AUTOSAR XML (schema 4-2-2)
package /ComponentTypes
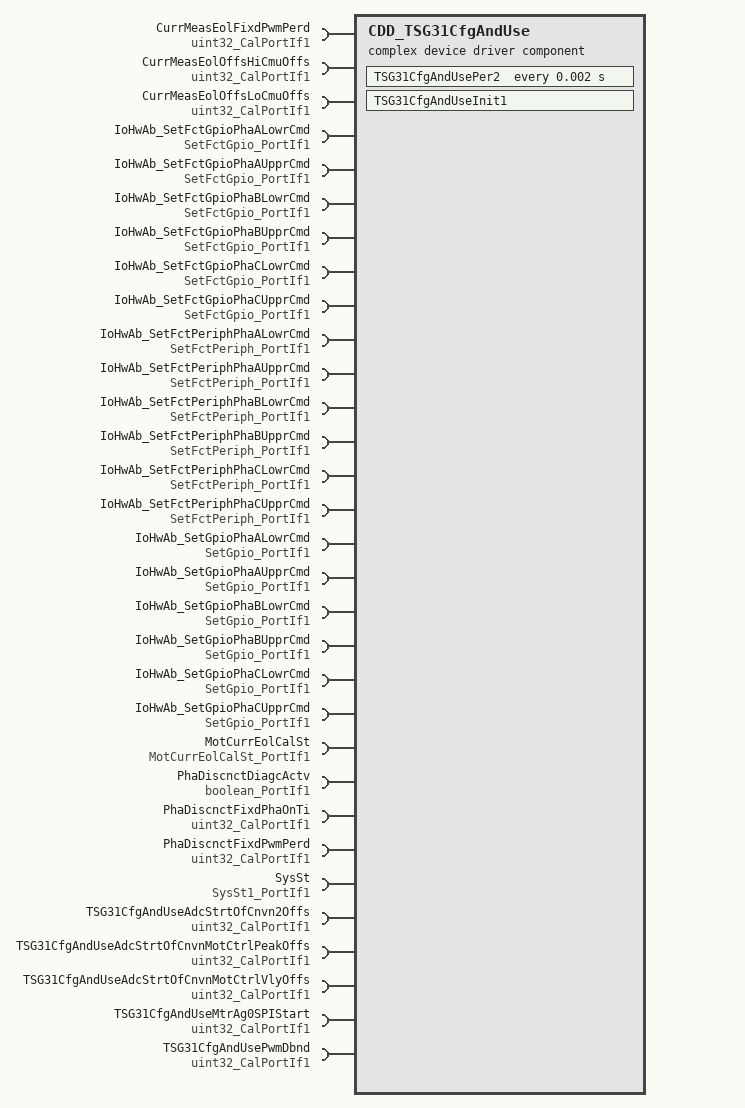
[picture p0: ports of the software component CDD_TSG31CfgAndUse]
  complex device driver sw component type CDD_TSG31CfgAndUse
    31 x require port:
      CurrMeasEolFixdPwmPerd: parameter-require-com-spec{init-value=62500, parameter=Val}, required-interface=uint32_CalPortIf1
      CurrMeasEolOffsHiCmuOffs: parameter-require-com-spec{init-value=50000, parameter=Val}, required-interface=uint32_CalPortIf1
      CurrMeasEolOffsLoCmuOffs: parameter-require-com-spec{init-value=6250, parameter=Val}, required-interface=uint32_CalPortIf1
      IoHwAb_SetFctGpioPhaALowrCmd: client-com-spec=Oper, required-interface=SetFctGpio_PortIf1
      IoHwAb_SetFctGpioPhaAUpprCmd: client-com-spec=Oper, required-interface=SetFctGpio_PortIf1
      IoHwAb_SetFctGpioPhaBLowrCmd: client-com-spec=Oper, required-interface=SetFctGpio_PortIf1
      IoHwAb_SetFctGpioPhaBUpprCmd: client-com-spec=Oper, required-interface=SetFctGpio_PortIf1
      IoHwAb_SetFctGpioPhaCLowrCmd: client-com-spec=Oper, required-interface=SetFctGpio_PortIf1
      IoHwAb_SetFctGpioPhaCUpprCmd: client-com-spec=Oper, required-interface=SetFctGpio_PortIf1
      IoHwAb_SetFctPeriphPhaALowrCmd: client-com-spec=Oper, required-interface=SetFctPeriph_PortIf1
      IoHwAb_SetFctPeriphPhaAUpprCmd: client-com-spec=Oper, required-interface=SetFctPeriph_PortIf1
      IoHwAb_SetFctPeriphPhaBLowrCmd: client-com-spec=Oper, required-interface=SetFctPeriph_PortIf1
      IoHwAb_SetFctPeriphPhaBUpprCmd: client-com-spec=Oper, required-interface=SetFctPeriph_PortIf1
      IoHwAb_SetFctPeriphPhaCLowrCmd: client-com-spec=Oper, required-interface=SetFctPeriph_PortIf1
      IoHwAb_SetFctPeriphPhaCUpprCmd: client-com-spec=Oper, required-interface=SetFctPeriph_PortIf1
      IoHwAb_SetGpioPhaALowrCmd: client-com-spec=Oper, required-interface=SetGpio_PortIf1
      IoHwAb_SetGpioPhaAUpprCmd: client-com-spec=Oper, required-interface=SetGpio_PortIf1
      IoHwAb_SetGpioPhaBLowrCmd: client-com-spec=Oper, required-interface=SetGpio_PortIf1
      IoHwAb_SetGpioPhaBUpprCmd: client-com-spec=Oper, required-interface=SetGpio_PortIf1
      IoHwAb_SetGpioPhaCLowrCmd: client-com-spec=Oper, required-interface=SetGpio_PortIf1
      IoHwAb_SetGpioPhaCUpprCmd: client-com-spec=Oper, required-interface=SetGpio_PortIf1
      MotCurrEolCalSt: nonqueued-receiver-com-spec{data-element=Val, filter=data-filter-type=ALWAYS, init-value=0}, required-interface=MotCurrEolCalSt_PortIf1
      PhaDiscnctDiagcActv: nonqueued-receiver-com-spec{data-element=Logl, filter=data-filter-type=ALWAYS, init-value=0}, required-interface=boolean_PortIf1
      PhaDiscnctFixdPhaOnTi: parameter-require-com-spec{init-value=6250, parameter=Val}, required-interface=uint32_CalPortIf1
      PhaDiscnctFixdPwmPerd: parameter-require-com-spec{init-value=62500, parameter=Val}, required-interface=uint32_CalPortIf1
      SysSt: nonqueued-receiver-com-spec{data-element=Val, filter=data-filter-type=ALWAYS, init-value=3}, required-interface=SysSt1_PortIf1
      TSG31CfgAndUseAdcStrtOfCnvn2Offs: parameter-require-com-spec{init-value=5000, parameter=Val}, required-interface=uint32_CalPortIf1
      TSG31CfgAndUseAdcStrtOfCnvnMotCtrlPeakOffs: parameter-require-com-spec{init-value=6000, parameter=Val}, required-interface=uint32_CalPortIf1
      TSG31CfgAndUseAdcStrtOfCnvnMotCtrlVlyOffs: parameter-require-com-spec{init-value=7000, parameter=Val}, required-interface=uint32_CalPortIf1
      TSG31CfgAndUseMtrAg0SPIStart: parameter-require-com-spec{init-value=1000, parameter=Val}, required-interface=uint32_CalPortIf1
      TSG31CfgAndUsePwmDbnd: parameter-require-com-spec{init-value=200, parameter=Val}, required-interface=uint32_CalPortIf1
    behavior CDD_TSG31CfgAndUse_InternalBehavior
      ar-typed-per-instance-memorys:
        9 x data, all with sw-calibration-access=READ-ONLY:
          MissUpdCoarse: type=uint16
          MissUpdFine: type=uint16
          MissUpdIninCntr: type=uint8
          MissUpdMaxCntr: type=uint16
          MissUpdMinCntr: type=uint16
          TSG31CfgAndUseAdcStrtOfCnvnPeak: type=uint32
          TSG31CfgAndUseMotAg0SPIStart: type=uint32
          TSG31CfgAndUsePhaDiscntActvdStPrev: type=boolean
          TSG31CfgAndUseSysStEnaPrev: type=boolean
      init event CDD_TSG31CfgAndUse_InitEvent: start-on-event=TSG31CfgAndUseInit1
      timing event TMT_TSG31CfgAndUsePer2: start-on-event=TSG31CfgAndUsePer2, period=0.002
      runnable TSG31CfgAndUseInit1
        12 x sync call, all with timeout=0:
          SC_IoHwAb_SetFctGpioPhaALowrCmd_Oper: operation=IoHwAb_SetFctGpioPhaALowrCmd.Oper
          SC_IoHwAb_SetFctGpioPhaAUpprCmd_Oper: operation=IoHwAb_SetFctGpioPhaAUpprCmd.Oper
          SC_IoHwAb_SetFctGpioPhaBLowrCmd_Oper: operation=IoHwAb_SetFctGpioPhaBLowrCmd.Oper
          SC_IoHwAb_SetFctGpioPhaBUpprCmd_Oper: operation=IoHwAb_SetFctGpioPhaBUpprCmd.Oper
          SC_IoHwAb_SetFctGpioPhaCLowrCmd_Oper: operation=IoHwAb_SetFctGpioPhaCLowrCmd.Oper
          SC_IoHwAb_SetFctGpioPhaCUpprCmd_Oper: operation=IoHwAb_SetFctGpioPhaCUpprCmd.Oper
          SC_IoHwAb_SetGpioPhaALowrCmd_Oper: operation=IoHwAb_SetGpioPhaALowrCmd.Oper
          SC_IoHwAb_SetGpioPhaAUpprCmd_Oper: operation=IoHwAb_SetGpioPhaAUpprCmd.Oper
          SC_IoHwAb_SetGpioPhaBLowrCmd_Oper: operation=IoHwAb_SetGpioPhaBLowrCmd.Oper
          SC_IoHwAb_SetGpioPhaBUpprCmd_Oper: operation=IoHwAb_SetGpioPhaBUpprCmd.Oper
          SC_IoHwAb_SetGpioPhaCLowrCmd_Oper: operation=IoHwAb_SetGpioPhaCLowrCmd.Oper
          SC_IoHwAb_SetGpioPhaCUpprCmd_Oper: operation=IoHwAb_SetGpioPhaCUpprCmd.Oper
      runnable TSG31CfgAndUsePer2
        data-receive-point-by-arguments:
          access REC_MotCurrEolCalSt_Val: accessed-variable=MotCurrEolCalSt.Val
          access REC_PhaDiscnctDiagcActv_Logl: accessed-variable=PhaDiscnctDiagcActv.Logl
          access REC_SysSt_Val: accessed-variable=SysSt.Val
        18 x sync call, all with timeout=0:
          SC_IoHwAb_SetFctGpioPhaALowrCmd_Oper: operation=IoHwAb_SetFctGpioPhaALowrCmd.Oper
          SC_IoHwAb_SetFctGpioPhaAUpprCmd_Oper: operation=IoHwAb_SetFctGpioPhaAUpprCmd.Oper
          SC_IoHwAb_SetFctGpioPhaBLowrCmd_Oper: operation=IoHwAb_SetFctGpioPhaBLowrCmd.Oper
          SC_IoHwAb_SetFctGpioPhaBUpprCmd_Oper: operation=IoHwAb_SetFctGpioPhaBUpprCmd.Oper
          SC_IoHwAb_SetFctGpioPhaCLowrCmd_Oper: operation=IoHwAb_SetFctGpioPhaCLowrCmd.Oper
          SC_IoHwAb_SetFctGpioPhaCUpprCmd_Oper: operation=IoHwAb_SetFctGpioPhaCUpprCmd.Oper
          SC_IoHwAb_SetFctPeriphPhaALowrCmd_Oper: operation=IoHwAb_SetFctPeriphPhaALowrCmd.Oper
          SC_IoHwAb_SetFctPeriphPhaAUpprCmd_Oper: operation=IoHwAb_SetFctPeriphPhaAUpprCmd.Oper
          SC_IoHwAb_SetFctPeriphPhaBLowrCmd_Oper: operation=IoHwAb_SetFctPeriphPhaBLowrCmd.Oper
          SC_IoHwAb_SetFctPeriphPhaBUpprCmd_Oper: operation=IoHwAb_SetFctPeriphPhaBUpprCmd.Oper
          SC_IoHwAb_SetFctPeriphPhaCLowrCmd_Oper: operation=IoHwAb_SetFctPeriphPhaCLowrCmd.Oper
          SC_IoHwAb_SetFctPeriphPhaCUpprCmd_Oper: operation=IoHwAb_SetFctPeriphPhaCUpprCmd.Oper
          SC_IoHwAb_SetGpioPhaALowrCmd_Oper: operation=IoHwAb_SetGpioPhaALowrCmd.Oper
          SC_IoHwAb_SetGpioPhaAUpprCmd_Oper: operation=IoHwAb_SetGpioPhaAUpprCmd.Oper
          SC_IoHwAb_SetGpioPhaBLowrCmd_Oper: operation=IoHwAb_SetGpioPhaBLowrCmd.Oper
          SC_IoHwAb_SetGpioPhaBUpprCmd_Oper: operation=IoHwAb_SetGpioPhaBUpprCmd.Oper
          SC_IoHwAb_SetGpioPhaCLowrCmd_Oper: operation=IoHwAb_SetGpioPhaCLowrCmd.Oper
          SC_IoHwAb_SetGpioPhaCUpprCmd_Oper: operation=IoHwAb_SetGpioPhaCUpprCmd.Oper
  swc implementation CDD_TSG31CfgAndUse_Implementation: behavior=CDD_TSG31CfgAndUse_InternalBehavior
    code-descriptors:
      code Default: artifact-descriptors=autosar-engineering-object={short-label=Default, category=SWSRC}
